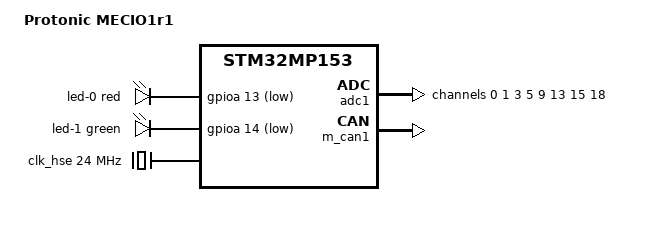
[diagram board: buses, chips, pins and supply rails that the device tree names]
// SPDX-License-Identifier: (GPL-2.0+ OR BSD-3-Clause)
/*
 * Copyright (C) Protonic Holland
 * Author: David Jander <david@protonic.nl>
 */
/dts-v1/;

#include "stm32mp153.dtsi"
#include "stm32mp15xc.dtsi"
#include "stm32mp15-pinctrl.dtsi"
#include "stm32mp15xxaa-pinctrl.dtsi"
#include "stm32mp15x-mecio1-io.dtsi"
#include <dt-bindings/gpio/gpio.h>
#include <dt-bindings/input/input.h>
#include <dt-bindings/leds/common.h>

/ {
	model = "Protonic MECIO1r1";
	compatible = "prt,mecio1r1", "st,stm32mp153";

	led {
		compatible = "gpio-leds";

		led-0 {
			color = <LED_COLOR_ID_RED>;
			function = LED_FUNCTION_DEBUG;
			gpios = <&gpioa 13 GPIO_ACTIVE_LOW>;
		};

		led-1 {
			color = <LED_COLOR_ID_GREEN>;
			function = LED_FUNCTION_DEBUG;
			gpios = <&gpioa 14 GPIO_ACTIVE_LOW>;
			linux,default-trigger = "heartbeat";
		};
	};
};

&adc1 {
	channel@0 {
		reg = <0>;
		st,min-sample-time-ns = <20000>;
		label = "p24v_hpdcm";
	};

	channel@1 {
		reg = <1>;
		st,min-sample-time-ns = <20000>;
		label = "p24v_stp";
	};

	channel@3 {
		reg = <3>;
		st,min-sample-time-ns = <200000>;
		label = "phint1_ain";
	};

	channel@5 {
		reg = <5>;
		st,min-sample-time-ns = <20000>;
		label = "hpout1_i";
	};

	channel@9 {
		reg = <9>;
		st,min-sample-time-ns = <20000>;
		label = "hpout0_i";
	};

	channel@13 {
		reg = <13>;
		st,min-sample-time-ns = <20000>;
		label = "hpdcm0_i2";
	};

	channel@15 {
		reg = <15>;
		st,min-sample-time-ns = <20000>;
		label = "hpdcm1_i2";
	};

	channel@18 {
		reg = <18>;
		st,min-sample-time-ns = <20000>;
		label = "hpdcm0_i1";
	};
};

&clk_hse {
	clock-frequency = <24000000>;
};

&m_can1 {
	pinctrl-names = "default", "sleep";
	pinctrl-0 = <&m_can1_pins_b>;
	pinctrl-1 = <&m_can1_sleep_pins_b>;
	status = "okay";
};
